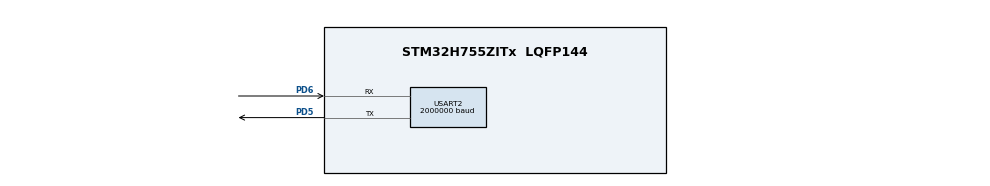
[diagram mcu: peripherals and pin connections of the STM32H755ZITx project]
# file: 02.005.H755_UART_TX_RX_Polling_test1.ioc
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CortexM4.IPs=FATFS_M4\:I,FREERTOS_M4\:I,IWDG2\:I,RCC,WWDG2\:I,DMA,BDMA,MDMA,NVIC2\:I,ETH,DEBUG,PDM2PCM_M4\:I,PWR,RESMGR_UTILITY,SYS_M4\:I,USB_DEVICE_M4\:I,USB_HOST_M4\:I,CORTEX_M4\:I,GPIO,OPENAMP_M4\:I,VREFBUF,NUCLEO-H755ZI-Q
CortexM7.IPs=FATFS_M7\:I,FREERTOS_M7\:I,IWDG1\:I,RCC\:I,WWDG1\:I,DMA\:I,BDMA\:I,MDMA\:I,NVIC1\:I,ETH\:I,USB_OTG_FS\:I,SYS\:I,CORTEX_M7\:I,DEBUG\:I,PDM2PCM_M7\:I,PWR\:I,RESMGR_UTILITY\:I,USB_DEVICE_M7\:I,USB_HOST_M7\:I,GPIO\:I,OPENAMP_M7\:I,VREFBUF\:I,NUCLEO-H755ZI-Q\:I,MEMORYMAP\:I,USART2\:I
Mcu.Family=STM32H7
Mcu.Name=STM32H755ZITx
Mcu.Package=LQFP144
NVIC1.PriorityGroup=NVIC_PRIORITYGROUP_4
NVIC2.PriorityGroup=NVIC_PRIORITYGROUP_4
PD5.Mode=Asynchronous
PD5.PinAttribute=CortexM7
PD5.Signal=USART2_TX
PD6.Mode=Asynchronous
PD6.PinAttribute=CortexM7
PD6.Signal=USART2_RX
ProjectManager.HeapSize=M4-0x200,M7-0x200
ProjectManager.StackSize=M4-0x400,M7-0x400
ProjectManager.TargetToolchain=STM32CubeIDE
RCC.ADCFreq_Value=129000000
RCC.APB1Freq_Value=100000000
RCC.APB2Freq_Value=100000000
RCC.APB3Freq_Value=100000000
RCC.APB4Freq_Value=100000000
RCC.CortexFreq_Value=400000000
RCC.D1PPRE=RCC_APB3_DIV2
RCC.D2PPRE1=RCC_APB1_DIV2
RCC.D2PPRE2=RCC_APB2_DIV2
RCC.D3PPRE=RCC_APB4_DIV2
RCC.DIVM1=4
RCC.DIVN1=50
RCC.DIVQ1=5
RCC.HCLKFreq_Value=200000000
RCC.HPRE=RCC_HCLK_DIV2
RCC.PLL2FRACN=0
RCC.PLL3FRACN=0
RCC.PLLFRACN=0
RCC.SYSCLKFreq_VALUE=400000000
RCC.SYSCLKSource=RCC_SYSCLKSOURCE_PLLCLK
RCC.SupplySource=PWR_DIRECT_SMPS_SUPPLY
RCC.USBFreq_Value=160000000
USART2.BaudRate=2000000
USART2.VirtualMode-Asynchronous=VM_ASYNC
VP_MEMORYMAP_VS_MEMORYMAP.Mode=CurAppReg
VP_SYS_M4_VS_Systick.Mode=SysTick
board=NUCLEO-H755ZI-Q

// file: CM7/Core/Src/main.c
/* USER CODE BEGIN Header */
/**
  ******************************************************************************
  * @file           : main.c
  * @brief          : Main program body
  ******************************************************************************
  * @attention
  *
  * Copyright (c) 2025 STMicroelectronics.
  * All rights reserved.
  *
  * This software is licensed under terms that can be found in the LICENSE file
  * in the root directory of this software component.
  * If no LICENSE file comes with this software, it is provided AS-IS.
  *
  ******************************************************************************
  */
/* USER CODE END Header */
#include "main.h"

/* USER CODE BEGIN Includes */
#include <stdio.h>
#include <string.h>
#include <stddef.h>
#include <stdarg.h>
#include <stdbool.h>
#include <stdlib.h>
/* USER CODE END Includes */

/* USER CODE BEGIN PD */

/* DUAL_CORE_BOOT_SYNC_SEQUENCE: Define for dual core boot synchronization    */
/*                             demonstration code based on hardware semaphore */
/* This define is present in both CM7/CM4 projects                            */
/* To comment when developping/debugging on a single core                     */
#define DUAL_CORE_BOOT_SYNC_SEQUENCE

#if defined(DUAL_CORE_BOOT_SYNC_SEQUENCE)
#ifndef HSEM_ID_0
#define HSEM_ID_0 (0U) /* HW semaphore 0*/
#endif
#endif /* DUAL_CORE_BOOT_SYNC_SEQUENCE */

/* USER CODE END PD */

UART_HandleTypeDef huart4;

void SystemClock_Config(void);
static void MX_GPIO_Init(void);
static void MX_USART2_UART_Init(void);

/* USER CODE BEGIN 0 */
void DebugPrint(const char *format, ...)
{
    char uartBuffer[250];
    va_list args;
    va_start(args, format);

    vsnprintf(uartBuffer, sizeof(uartBuffer), format, args);
    va_end(args);

    HAL_UART_Transmit(&huart4, (uint8_t*)uartBuffer, strlen(uartBuffer), HAL_MAX_DELAY);
}

void uart_rx_polling(void)
{
    uint8_t rx_byte;
    static uint32_t total_pos = 0;

    // Polling loop — call periodically in main loop or a scheduler task
    if (HAL_UART_Receive(&huart4, &rx_byte, 1, 0) == HAL_OK)
    {
        // Byte received successfully
        DebugPrint("\r\nGot: '%c' (0x%02X) at pos %lu\r\n\r\n",
                   rx_byte, rx_byte, total_pos++);
    }
}

/* USER CODE END 0 */

int main(void)
{

/* USER CODE BEGIN Boot_Mode_Sequence_0 */
#if defined(DUAL_CORE_BOOT_SYNC_SEQUENCE)
  int32_t timeout;
#endif /* DUAL_CORE_BOOT_SYNC_SEQUENCE */
/* USER CODE END Boot_Mode_Sequence_0 */

/* USER CODE BEGIN Boot_Mode_Sequence_1 */
#if defined(DUAL_CORE_BOOT_SYNC_SEQUENCE)
  /* Wait until CPU2 boots and enters in stop mode or timeout*/
  timeout = 0xFFFF;
  while((__HAL_RCC_GET_FLAG(RCC_FLAG_D2CKRDY) != RESET) && (timeout-- > 0));
  if ( timeout < 0 )
  {
  Error_Handler();
  }
#endif /* DUAL_CORE_BOOT_SYNC_SEQUENCE */
/* USER CODE END Boot_Mode_Sequence_1 */
  /* MCU Configuration--------------------------------------------------------*/

  /* Reset of all peripherals, Initializes the Flash interface and the Systick. */
  HAL_Init();

  /* Configure the system clock */
  SystemClock_Config();
/* USER CODE BEGIN Boot_Mode_Sequence_2 */
#if defined(DUAL_CORE_BOOT_SYNC_SEQUENCE)
/* When system initialization is finished, Cortex-M7 will release Cortex-M4 by means of
HSEM notification */
/*HW semaphore Clock enable*/
__HAL_RCC_HSEM_CLK_ENABLE();
/*Take HSEM */
HAL_HSEM_FastTake(HSEM_ID_0);
/*Release HSEM in order to notify the CPU2(CM4)*/
HAL_HSEM_Release(HSEM_ID_0,0);
/* wait until CPU2 wakes up from stop mode */
timeout = 0xFFFF;
while((__HAL_RCC_GET_FLAG(RCC_FLAG_D2CKRDY) == RESET) && (timeout-- > 0));
if ( timeout < 0 )
{
Error_Handler();
}
#endif /* DUAL_CORE_BOOT_SYNC_SEQUENCE */
/* USER CODE END Boot_Mode_Sequence_2 */

  /* Initialize all configured peripherals */
  MX_GPIO_Init();
  MX_USART2_UART_Init();
  /* USER CODE BEGIN 2 */
  DebugPrint("UART Polling tested!\r\n");
  /* USER CODE END 2 */

  /* Infinite loop */
  while (1)
  {

    /* USER CODE BEGIN 3 */
	  uart_rx_polling();
  }
  /* USER CODE END 3 */
}

void SystemClock_Config(void)
{
  RCC_OscInitTypeDef RCC_OscInitStruct = {0};
  RCC_ClkInitTypeDef RCC_ClkInitStruct = {0};

  /** Supply configuration update enable
  */
  HAL_PWREx_ConfigSupply(PWR_DIRECT_SMPS_SUPPLY);

  /** Configure the main internal regulator output voltage
  */
  __HAL_PWR_VOLTAGESCALING_CONFIG(PWR_REGULATOR_VOLTAGE_SCALE1);

  while(!__HAL_PWR_GET_FLAG(PWR_FLAG_VOSRDY)) {}

  /** Initializes the RCC Oscillators according to the specified parameters
  * in the RCC_OscInitTypeDef structure.
  */
  RCC_OscInitStruct.OscillatorType = RCC_OSCILLATORTYPE_HSI;
  RCC_OscInitStruct.HSIState = RCC_HSI_DIV1;
  RCC_OscInitStruct.HSICalibrationValue = RCC_HSICALIBRATION_DEFAULT;
  RCC_OscInitStruct.PLL.PLLState = RCC_PLL_ON;
  RCC_OscInitStruct.PLL.PLLSource = RCC_PLLSOURCE_HSI;
  RCC_OscInitStruct.PLL.PLLM = 4;
  RCC_OscInitStruct.PLL.PLLN = 50;
  RCC_OscInitStruct.PLL.PLLP = 2;
  RCC_OscInitStruct.PLL.PLLQ = 5;
  RCC_OscInitStruct.PLL.PLLR = 2;
  RCC_OscInitStruct.PLL.PLLRGE = RCC_PLL1VCIRANGE_3;
  RCC_OscInitStruct.PLL.PLLVCOSEL = RCC_PLL1VCOWIDE;
  RCC_OscInitStruct.PLL.PLLFRACN = 0;
  if (HAL_RCC_OscConfig(&RCC_OscInitStruct) != HAL_OK)
  {
    Error_Handler();
  }

  /** Initializes the CPU, AHB and APB buses clocks
  */
  RCC_ClkInitStruct.ClockType = RCC_CLOCKTYPE_HCLK|RCC_CLOCKTYPE_SYSCLK
                              |RCC_CLOCKTYPE_PCLK1|RCC_CLOCKTYPE_PCLK2
                              |RCC_CLOCKTYPE_D3PCLK1|RCC_CLOCKTYPE_D1PCLK1;
  RCC_ClkInitStruct.SYSCLKSource = RCC_SYSCLKSOURCE_PLLCLK;
  RCC_ClkInitStruct.SYSCLKDivider = RCC_SYSCLK_DIV1;
  RCC_ClkInitStruct.AHBCLKDivider = RCC_HCLK_DIV2;
  RCC_ClkInitStruct.APB3CLKDivider = RCC_APB3_DIV2;
  RCC_ClkInitStruct.APB1CLKDivider = RCC_APB1_DIV2;
  RCC_ClkInitStruct.APB2CLKDivider = RCC_APB2_DIV2;
  RCC_ClkInitStruct.APB4CLKDivider = RCC_APB4_DIV2;

  if (HAL_RCC_ClockConfig(&RCC_ClkInitStruct, FLASH_LATENCY_2) != HAL_OK)
  {
    Error_Handler();
  }
}

static void MX_USART2_UART_Init(void)
{

  huart4.Instance = USART2;
  huart4.Init.BaudRate = 2000000;
  huart4.Init.WordLength = UART_WORDLENGTH_8B;
  huart4.Init.StopBits = UART_STOPBITS_1;
  huart4.Init.Parity = UART_PARITY_NONE;
  huart4.Init.Mode = UART_MODE_TX_RX;
  huart4.Init.HwFlowCtl = UART_HWCONTROL_NONE;
  huart4.Init.OverSampling = UART_OVERSAMPLING_16;
  huart4.Init.OneBitSampling = UART_ONE_BIT_SAMPLE_DISABLE;
  huart4.Init.ClockPrescaler = UART_PRESCALER_DIV1;
  huart4.AdvancedInit.AdvFeatureInit = UART_ADVFEATURE_NO_INIT;
  if (HAL_UART_Init(&huart4) != HAL_OK)
  {
    Error_Handler();
  }
  if (HAL_UARTEx_SetTxFifoThreshold(&huart4, UART_TXFIFO_THRESHOLD_1_8) != HAL_OK)
  {
    Error_Handler();
  }
  if (HAL_UARTEx_SetRxFifoThreshold(&huart4, UART_RXFIFO_THRESHOLD_1_8) != HAL_OK)
  {
    Error_Handler();
  }
  if (HAL_UARTEx_DisableFifoMode(&huart4) != HAL_OK)
  {
    Error_Handler();
  }

}

static void MX_GPIO_Init(void)
{

  /* GPIO Ports Clock Enable */
  __HAL_RCC_GPIOD_CLK_ENABLE();

}

void Error_Handler(void)
{
  __disable_irq();
  while (1)
  {
  }
}
